VERSION ""

NS_ :

BS_:

BU_: STM32 RaspberryPi

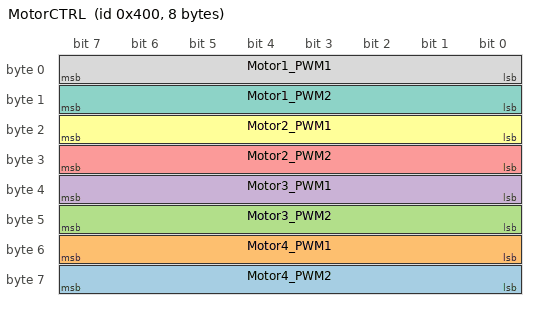
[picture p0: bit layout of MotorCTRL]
BO_ 1024 MotorCTRL: 8 RaspberryPi
 SG_ Motor4_PWM2 : 56|8@1+ (1,0) [0|100] "duty"  STM32
 SG_ Motor4_PWM1 : 48|8@1+ (1,0) [0|100] "duty"  STM32
 SG_ Motor3_PWM2 : 40|8@1+ (1,0) [0|100] "duty"  STM32
 SG_ Motor3_PWM1 : 32|8@1+ (1,0) [0|100] "duty"  STM32
 SG_ Motor2_PWM2 : 24|8@1+ (1,0) [0|100] "duty"  STM32
 SG_ Motor2_PWM1 : 16|8@1+ (1,0) [0|100] "duty"  STM32
 SG_ Motor1_PWM2 : 8|8@1+ (1,0) [0|100] "duty"  STM32
 SG_ Motor1_PWM1 : 0|8@1+ (1,0) [0|100] "duty"  STM32

BA_DEF_  "BusType" STRING ;
BA_DEF_DEF_  "BusType" "CAN";
